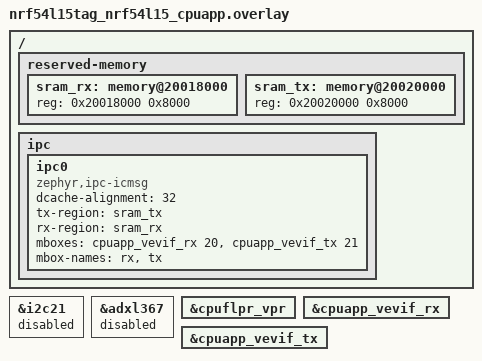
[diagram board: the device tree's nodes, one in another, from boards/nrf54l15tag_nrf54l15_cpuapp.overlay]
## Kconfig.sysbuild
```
# SPDX-License-Identifier: Apache-2.0

config PARTITION_MANAGER
	default n

config REMOTE_BOARD
	string
	default "nrf54l15tag/nrf54l15/cpuflpr" if BOARD_NRF54L15TAG_NRF54L15_CPUAPP

source "share/sysbuild/Kconfig"
```

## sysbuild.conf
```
# Gera merged_<board>.hex no build dir (o hex que vai para tag/hex/)
SB_CONFIG_MERGED_HEX_FILES=y
```

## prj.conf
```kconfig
CONFIG_BT=y
CONFIG_LOG=y
CONFIG_BT_DEVICE_NAME="Test beacon"

# TX power: default is 0 dBm (CONFIG_BT_CTLR_TX_PWR_0, applied automatically
# just from CONFIG_BT=y). Uncomment ONE line below to override - works with
# the SoftDevice Controller too. Valid discrete values for the nRF54L15
# range from -10 dBm to +8 dBm (see zephyr/subsys/bluetooth/controller/
# Kconfig, options gated on SOC_COMPATIBLE_NRF54LX, for the full list).
# CONFIG_BT_CTLR_TX_PWR_MINUS_10=y  # -10 dBm
# CONFIG_BT_CTLR_TX_PWR_0=y         # 0 dBm (default)
# CONFIG_BT_CTLR_TX_PWR_PLUS_4=y    # +4 dBm
# CONFIG_BT_CTLR_TX_PWR_PLUS_8=y    # +8 dBm

# Motion state arrives over IPC from the FLPR core (see remote/src/main.c)
# instead of a local ADXL367 driver - no CONFIG_SENSOR needed on this image.
CONFIG_IPC_SERVICE=y
CONFIG_MBOX=y

# Route logging to SEGGER RTT - same rationale as tag/01-motion-adv.
CONFIG_USE_SEGGER_RTT=y
CONFIG_LOG_BACKEND_RTT=y
CONFIG_LOG_BACKEND_UART=n
CONFIG_UART_CONSOLE=n
CONFIG_LOG_MODE_DEFERRED=y
CONFIG_LOG_BUFFER_SIZE=4096
CONFIG_SEGGER_RTT_BUFFER_SIZE_UP=4096
```

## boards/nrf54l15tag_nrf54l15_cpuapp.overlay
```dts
/*
 * The ADXL367 accelerometer and its I2C bus now belong to the FLPR core
 * (see remote/boards/nrf54l15tag_nrf54l15_cpuflpr.overlay) - disable both
 * here so the app core doesn't also try to own them.
 *
 * cpuflpr_vpr enables the FLPR core itself: without this, the app core
 * never launches it (see the design spec's "Boot do FLPR" section - the
 * FLPR can't self-boot from reset on this SoC). This alone is necessary
 * but not sufficient - CONFIG_NORDIC_VPR_LAUNCHER also requires the vpr
 * node to carry an `execution-memory` property, which only the nordic-flpr
 * snippet provides (along with the SRAM/RRAM carve-out this image's ipc0
 * regions below assume). The snippet is force-applied in sysbuild.cmake.
 */

&i2c21 {
	status = "disabled";
};

&adxl367 {
	status = "disabled";
};

&cpuflpr_vpr {
	status = "okay";
};

/*
 * ipc0: icmsg channel to the FLPR core over shared SRAM + VEVIF doorbells.
 * Addresses/channel numbers match Nordic's own cpuapp<->cpuflpr icmsg
 * example for this SoC family (nrf/samples/event_manager_proxy, NCS
 * v3.4.0) - tx/rx are swapped on the FLPR side, see the matching overlay
 * in remote/boards/.
 */
/ {
	reserved-memory {
		#address-cells = <1>;
		#size-cells = <1>;
		ranges;

		sram_rx: memory@20018000 {
			reg = <0x20018000 0x8000>;
		};

		sram_tx: memory@20020000 {
			reg = <0x20020000 0x8000>;
		};
	};

	ipc {
		ipc0: ipc0 {
			compatible = "zephyr,ipc-icmsg";
			dcache-alignment = <32>;
			tx-region = <&sram_tx>;
			rx-region = <&sram_rx>;
			mboxes = <&cpuapp_vevif_rx 20>, <&cpuapp_vevif_tx 21>;
			mbox-names = "rx", "tx";
			status = "okay";
		};
	};
};

&cpuapp_vevif_rx {
	status = "okay";
};

&cpuapp_vevif_tx {
	status = "okay";
};
```

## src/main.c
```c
/* main.c - Motion-adaptive advertising, FLPR variant: BLE/LED only. Motion
 * state is driven by IPC events from the FLPR core over the "motion"
 * ipc_service endpoint (see remote/src/main.c for the sending side).
 */

/*
 * Copyright (c) 2015-2016 Intel Corporation
 * Copyright (c) 2026 Nordic Semiconductor ASA
 *
 * SPDX-License-Identifier: Apache-2.0
 */

#include <zephyr/types.h>
#include <stddef.h>
#include <zephyr/kernel.h>
#include <zephyr/sys/util.h>
#include <zephyr/device.h>
#include <zephyr/devicetree.h>
#include <zephyr/drivers/gpio.h>
#include <zephyr/logging/log.h>
#include <zephyr/ipc/ipc_service.h>

#include <zephyr/bluetooth/bluetooth.h>
#include <zephyr/bluetooth/hci.h>

LOG_MODULE_REGISTER(main, LOG_LEVEL_INF);

#define DEVICE_NAME CONFIG_BT_DEVICE_NAME
#define DEVICE_NAME_LEN (sizeof(DEVICE_NAME) - 1)

/*
 * Custom Manufacturer Specific Data (AD type 0xFF) - identical layout to
 * tag/01-motion-adv. byte 5 (state) is set from the IPC message received
 * from the FLPR core instead of a local sensor callback.
 */
#define MFG_DATA_STATE_IDX   5
#define MFG_STATE_STATIONARY 0x00
#define MFG_STATE_MOVING     0x01

static uint8_t mfg_data[] = {
	0x59, 0x00,
	0xAA, 0xBB, 0xCC,
	MFG_STATE_STATIONARY,
};

static const struct bt_data ad[] = {
	BT_DATA_BYTES(BT_DATA_FLAGS, BT_LE_AD_NO_BREDR),
	BT_DATA(BT_DATA_MANUFACTURER_DATA, mfg_data, sizeof(mfg_data)),
};

static const struct bt_data sd[] = {
	BT_DATA(BT_DATA_NAME_COMPLETE, DEVICE_NAME, DEVICE_NAME_LEN),
};

static const struct bt_le_adv_param *adv_param_moving = BT_LE_ADV_PARAM(
	BT_LE_ADV_OPT_USE_IDENTITY,
	BT_GAP_MS_TO_ADV_INTERVAL(500), BT_GAP_MS_TO_ADV_INTERVAL(520), NULL);

static const struct bt_le_adv_param *adv_param_stationary = BT_LE_ADV_PARAM(
	BT_LE_ADV_OPT_USE_IDENTITY,
	BT_GAP_MS_TO_ADV_INTERVAL(2000), BT_GAP_MS_TO_ADV_INTERVAL(2020), NULL);

/* RGB LED (individual GPIO channels of LED1): blue = stationary, red = moving */
static const struct gpio_dt_spec led_red = GPIO_DT_SPEC_GET(DT_NODELABEL(led1_red), gpios);
static const struct gpio_dt_spec led_blue = GPIO_DT_SPEC_GET(DT_NODELABEL(led1_blue), gpios);

static bool is_moving;

static void set_led(bool moving)
{
	gpio_pin_set_dt(&led_red, moving);
	gpio_pin_set_dt(&led_blue, !moving);
}

static void adv_start(const struct bt_le_adv_param *param)
{
	int err = bt_le_adv_start(param, ad, ARRAY_SIZE(ad), sd, ARRAY_SIZE(sd));

	if (err) {
		LOG_ERR("Advertising failed to start (err %d)", err);
	}
}

static void enter_moving_state(void)
{
	is_moving = true;
	LOG_INF("Motion detected: continuous advertising, ~500 ms interval");

	(void)bt_le_adv_stop();
	mfg_data[MFG_DATA_STATE_IDX] = MFG_STATE_MOVING;
	set_led(true);
	adv_start(adv_param_moving);
}

static void enter_stationary_state(void)
{
	is_moving = false;
	LOG_INF("No motion: continuous advertising, ~2 s interval");

	(void)bt_le_adv_stop();
	mfg_data[MFG_DATA_STATE_IDX] = MFG_STATE_STATIONARY;
	set_led(false);
	adv_start(adv_param_stationary);
}

static struct ipc_ept motion_ept;

static void motion_bound_cb(void *priv)
{
	ARG_UNUSED(priv);
	LOG_INF("IPC endpoint 'motion' bound to FLPR");
}

static void motion_received_cb(const void *data, size_t len, void *priv)
{
	ARG_UNUSED(priv);

	if (len != 1) {
		LOG_WRN("Unexpected motion IPC payload length: %zu", len);
		return;
	}

	if (*(const uint8_t *)data == MFG_STATE_MOVING) {
		enter_moving_state();
	} else {
		enter_stationary_state();
	}
}

static void motion_error_cb(const char *message, void *priv)
{
	ARG_UNUSED(priv);
	LOG_ERR("IPC error: %s", message);
}

static const struct ipc_ept_cfg motion_ept_cfg = {
	.name = "motion",
	.cb = {
		.bound = motion_bound_cb,
		.received = motion_received_cb,
		.error = motion_error_cb,
	},
};

int main(void)
{
	int err;

	LOG_INF("Starting Motion-Adaptive Advertising Demo (FLPR variant)");

	gpio_pin_configure_dt(&led_red, GPIO_OUTPUT_INACTIVE);
	gpio_pin_configure_dt(&led_blue, GPIO_OUTPUT_INACTIVE);

	err = bt_enable(NULL);
	if (err) {
		LOG_ERR("Bluetooth init failed (err %d)", err);
		return 0;
	}
	LOG_INF("Bluetooth initialized");

	{
		const struct device *ipc_instance = DEVICE_DT_GET(DT_NODELABEL(ipc0));

		err = ipc_service_open_instance(ipc_instance);
		if (err < 0 && err != -EALREADY) {
			LOG_ERR("ipc_service_open_instance failed (err %d)", err);
		}

		err = ipc_service_register_endpoint(ipc_instance, &motion_ept, &motion_ept_cfg);
		if (err) {
			LOG_ERR("ipc_service_register_endpoint failed (err %d)", err);
		}
	}

	/* Start advertising in stationary state regardless of whether IPC
	 * registration above succeeded - fail open, matches the design
	 * spec's error-handling section (the demo shouldn't go silent just
	 * because the FLPR link isn't up).
	 */
	enter_stationary_state();

	for (uint32_t tick = 0;; tick++) {
		k_sleep(K_SECONDS(5));
		LOG_INF("[PING] alive, tick=%u, is_moving=%d", tick, is_moving);
	}

	return 0;
}
```
